AUTOSAR XML (schema 00049)
package /MICROSAR/Dcm_swc
  4 x mode declaration group, all with category=EXPLICIT_ORDER:
    DcmControlDtcSetting: initial-mode=ENABLEDTCSETTING, on-transition-value=2
      mode ENABLEDTCSETTING: value=0
      mode DISABLEDTCSETTING: value=1
    DcmEcuReset: initial-mode=NONE, on-transition-value=7
      7 x mode:
        NONE: value=0
        HARD: value=1
        KEYONOFF: value=2
        SOFT: value=3
        JUMPTOBOOTLOADER: value=4
        JUMPTOSYSSUPPLIERBOOTLOADER: value=5
        EXECUTE: value=6
    DcmDiagnosticSessionControl: initial-mode=DEFAULT_SESSION, on-transition-value=255
      mode DEFAULT_SESSION: value=1
      mode PROGRAMMING_SESSION: value=2
      mode EXTENDED_SESSION: value=3
    DcmCommunicationControl: initial-mode=DCM_ENABLE_RX_TX_NORM, on-transition-value=12
      12 x mode:
        DCM_ENABLE_RX_TX_NORM: value=0
        DCM_ENABLE_RX_DISABLE_TX_NORM: value=1
        DCM_DISABLE_RX_ENABLE_TX_NORM: value=2
        DCM_DISABLE_RX_TX_NORMAL: value=3
        DCM_ENABLE_RX_TX_NM: value=4
        DCM_ENABLE_RX_DISABLE_TX_NM: value=5
        DCM_DISABLE_RX_ENABLE_TX_NM: value=6
        DCM_DISABLE_RX_TX_NM: value=7
        DCM_ENABLE_RX_TX_NORM_NM: value=8
        DCM_ENABLE_RX_DISABLE_TX_NORM_NM: value=9
        DCM_DISABLE_RX_ENABLE_TX_NORM_NM: value=10
        DCM_DISABLE_RX_TX_NORM_NM: value=11
  data type mapping set DcmMappingSet  # Contains mapping for ModeDeclarationGroups which are provided by Dcm.
    mode-request-type-maps:
      implementation-data-type=Dcm_ControlDtcSettingType, mode-group=DcmControlDtcSetting
      implementation-data-type=Dcm_EcuResetType, mode-group=DcmEcuReset
      implementation-data-type=Dcm_DiagnosticSessionControlType, mode-group=DcmDiagnosticSessionControl
      implementation-data-type=Dcm_CommunicationModeType, mode-group=DcmCommunicationControl
package /MICROSAR/Dcm_swc/DataTypes
  70 x impl type:
    Dcm_ConfirmationStatusType: compu {0=DCM_RES_POS_OK, 1=DCM_RES_POS_NOT_OK, 2=DCM_RES_NEG_OK, 3=DCM_RES_NEG_NOT_OK}, range raw 0..3, implementation-data-type=uint8
    Dcm_OpStatusType: compu {0=DCM_INITIAL, 1=DCM_PENDING, 2=DCM_CANCEL, 3=DCM_FORCE_RCRRP_OK, 64=DCM_FORCE_RCRRP_NOT_OK}, range raw 0..64, implementation-data-type=uint8
    Dcm_NegativeResponseCodeType:
      compu {0=DCM_E_POSITIVERESPONSE, 16=DCM_E_GENERALREJECT, 17=DCM_E_SERVICENOTSUPPORTED, 18=DCM_E_SUBFUNCTIONNOTSUPPORTED, 19=DCM_E_INCORRECTMESSAGELENGTHORINVALIDFORMAT, 20=DCM_E_RESPONSETOOLONG, 33=DCM_E_BUSYREPEATREQUEST, 34=DCM_E_CONDITIONSNOTCORRECT, 36=DCM_E_REQUESTSEQUENCEERROR, 37=DCM_E_NORESPONSEFROMSUBNETCOMPONENT, 38=DCM_E_FAILUREPREVENTSEXECUTIONOFREQUESTEDACTION, 49=DCM_E_REQUESTOUTOFRANGE, 51=DCM_E_SECURITYACCESSDENIED, 52=DCM_E_AUTHENTICATIONREQUIRED, 53=DCM_E_INVALIDKEY, 54=DCM_E_EXCEEDNUMBEROFATTEMPTS, 55=DCM_E_REQUIREDTIMEDELAYNOTEXPIRED, 80=DCM_E_CVF_INVALIDTIMEPERIOD, 81=DCM_E_CVF_INVALIDSIGNATURE, 82=DCM_E_CVF_INVALIDCHAINOFTRUST, 83=DCM_E_CVF_INVALIDTYPE, 84=DCM_E_CVF_INVALIDFORMAT, 85=DCM_E_CVF_INVALIDCONTENT, 86=DCM_E_CVF_INVALIDSCOPE, 87=DCM_E_CVF_INVALIDCERTIFICATEREVOKED, 88=DCM_E_OWNERSHIPVERIFICATIONFAILED, 89=DCM_E_CHALLENGECALCULATIONFAILED, 112=DCM_E_UPLOADDOWNLOADNOTACCEPTED, 113=DCM_E_TRANSFERDATASUSPENDED, 114=DCM_E_GENERALPROGRAMMINGFAILURE, 115=DCM_E_WRONGBLOCKSEQUENCECOUNTER, 120=DCM_E_REQUESTCORRECTLYRECEIVEDRESPONSEPENDING, 126=DCM_E_SUBFUNCTIONNOTSUPPORTEDINACTIVESESSION, 127=DCM_E_SERVICENOTSUPPORTEDINACTIVESESSION, 129=DCM_E_RPMTOOHIGH, 130=DCM_E_RPMTOOLOW, 131=DCM_E_ENGINEISRUNNING, 132=DCM_E_ENGINEISNOTRUNNING, 133=DCM_E_ENGINERUNTIMETOOLOW, 134=DCM_E_TEMPERATURETOOHIGH, 135=DCM_E_TEMPERATURETOOLOW, 136=DCM_E_VEHICLESPEEDTOOHIGH, 137=DCM_E_VEHICLESPEEDTOOLOW, 138=DCM_E_THROTTLE_PEDALTOOHIGH, 139=DCM_E_THROTTLE_PEDALTOOLOW, 140=DCM_E_TRANSMISSIONRANGENOTINNEUTRAL, 141=DCM_E_TRANSMISSIONRANGENOTINGEAR, 143=DCM_E_BRAKESWITCH_NOTCLOSED, 144=DCM_E_SHIFTERLEVERNOTINPARK, 145=DCM_E_TORQUECONVERTERCLUTCHLOCKED, 146=DCM_E_VOLTAGETOOHIGH, 147=DCM_E_VOLTAGETOOLOW, 240..249=DCM_E_VMSCNC_0..DCM_E_VMSCNC_9, 250=DCM_E_VMSCNC_A, 251=DCM_E_VMSCNC_B, 252=DCM_E_VMSCNC_C, 253=DCM_E_VMSCNC_D, 254=DCM_E_VMSCNC_E}
      range raw 0..255
      implementation-data-type=uint8
    Dcm_ProtocolType: compu {0=DCM_OBD_ON_CAN, 1=DCM_OBD_ON_FLEXRAY, 2=DCM_OBD_ON_IP, 3=DCM_UDS_ON_CAN, 4=DCM_UDS_ON_FLEXRAY, 5=DCM_UDS_ON_IP, 12=DCM_NO_ACTIVE_PROTOCOL, 240..254=DCM_SUPPLIER_1..DCM_SUPPLIER_15}, range raw 0..254, implementation-data-type=uint8
    Dcm_RequestKindType: compu {0=DCM_REQ_KIND_NONE, 1=DCM_REQ_KIND_EXTERNAL, 2=DCM_REQ_KIND_ROE}, range raw 0..2, implementation-data-type=uint8
    Dcm_SecLevelType: compu {0=DCM_SEC_LEV_LOCKED, 1=DCM_SEC_LEV_L1, 2=DCM_SEC_LEV_L2}, range raw 0..2, implementation-data-type=uint8
    Dcm_SesCtrlType: compu {1=DCM_DEFAULT_SESSION, 2=DCM_PROGRAMMING_SESSION, 3=DCM_EXTENDED_DIAGNOSTIC_SESSION}, range raw 0..3, implementation-data-type=uint8
    Dcm_RequestDataArrayType: category=ARRAY, sw-calibration-access=READ-ONLY
      element Dcm_RequestDataArrayTypeElement: array-size=48, array-size-semantics=FIXED-SIZE, implementation-data-type=uint8
    Dcm_ControlDtcSettingType: compu {0=DCM_ENUM_ENABLEDTCSETTING, 1=DCM_ENUM_DISABLEDTCSETTING}, range raw 0..255, implementation-data-type=uint8
    Dcm_EcuResetType: compu {0=DCM_ENUM_NONE, 1=DCM_ENUM_HARD, 2=DCM_ENUM_KEYONOFF, 3=DCM_ENUM_SOFT, 4=DCM_ENUM_JUMPTOBOOTLOADER, 5=DCM_ENUM_JUMPTOSYSSUPPLIERBOOTLOADER, 6=DCM_ENUM_EXECUTE}, range raw 0..255, implementation-data-type=uint8
    Dcm_DiagnosticSessionControlType: compu {1=DCM_ENUM_DEFAULT_SESSION, 2=DCM_ENUM_PROGRAMMING_SESSION, 3=DCM_ENUM_EXTENDED_SESSION}, range raw 0..255, implementation-data-type=uint8
    Dcm_CommunicationModeType:
      compu {0=DCM_ENABLE_RX_TX_NORM, 1=DCM_ENABLE_RX_DISABLE_TX_NORM, 2=DCM_DISABLE_RX_ENABLE_TX_NORM, 3=DCM_DISABLE_RX_TX_NORMAL, 4=DCM_ENABLE_RX_TX_NM, 5=DCM_ENABLE_RX_DISABLE_TX_NM, 6=DCM_DISABLE_RX_ENABLE_TX_NM, 7=DCM_DISABLE_RX_TX_NM, 8=DCM_ENABLE_RX_TX_NORM_NM, 9=DCM_ENABLE_RX_DISABLE_TX_NORM_NM, 10=DCM_DISABLE_RX_ENABLE_TX_NORM_NM, 11=DCM_DISABLE_RX_TX_NORM_NM}
      range raw 0..255
      implementation-data-type=uint8
    Dcm_Data4ByteType: category=ARRAY, sw-calibration-access=READ-ONLY
      element Dcm_Data4ByteTypeElement: array-size=4, array-size-semantics=FIXED-SIZE, implementation-data-type=uint8
    Dcm_Data2ByteType: category=ARRAY, sw-calibration-access=READ-ONLY
      element Dcm_Data2ByteTypeElement: array-size=2, array-size-semantics=FIXED-SIZE, implementation-data-type=uint8
    Dcm_StartDataIn_SampleRoutineControl_In_Option0PrimitiveType: implementation-data-type=uint8
    Dcm_StartDataIn_SampleRoutineControl_In_Option0Type: implementation-data-type=Dcm_StartDataIn_SampleRoutineControl_In_Option0PrimitiveType
    Dcm_StartDataOut_SampleRoutineControl_Out_InitStatePrimitiveType: implementation-data-type=uint32
    Dcm_StartDataOut_SampleRoutineControl_Out_InitStateType: implementation-data-type=Dcm_StartDataOut_SampleRoutineControl_Out_InitStatePrimitiveType
    Dcm_StopDataOut_SampleRoutineControl_Out_StopStatePrimitiveType: implementation-data-type=uint32
    Dcm_StopDataOut_SampleRoutineControl_Out_StopStateType: implementation-data-type=Dcm_StopDataOut_SampleRoutineControl_Out_StopStatePrimitiveType
    Dcm_RequestDataOut_SampleRoutineControl_Out_ResultPrimitiveType: implementation-data-type=uint16
    Dcm_RequestDataOut_SampleRoutineControl_Out_ResultType: implementation-data-type=Dcm_RequestDataOut_SampleRoutineControl_Out_ResultPrimitiveType
    Dcm_StartDataIn_SampleRoutineControl_StartOnly_In_Option1ArrayType: implementation-data-type=uint8
    Dcm_StartDataIn_SampleRoutineControl_StartOnly_In_Option1Type: category=ARRAY, sw-calibration-access=READ-ONLY
      element Dcm_StartDataIn_SampleRoutineControl_StartOnly_In_Option1TypeElement: array-size=3, array-size-semantics=FIXED-SIZE, implementation-data-type=Dcm_StartDataIn_SampleRoutineControl_StartOnly_In_Option1ArrayType
    Dcm_RequestDataOut_SampleRoutineControl_StartOnly_Out_ResultPrimitiveType: implementation-data-type=uint32
    Dcm_RequestDataOut_SampleRoutineControl_StartOnly_Out_ResultType: implementation-data-type=Dcm_RequestDataOut_SampleRoutineControl_StartOnly_Out_ResultPrimitiveType
    Dcm_DataElement_DID_0xF413_DID_Data_PrimitiveType: implementation-data-type=uint16
    Dcm_DataElement_DID_0xF413_DID_DataType: implementation-data-type=Dcm_DataElement_DID_0xF413_DID_Data_PrimitiveType
    Dcm_DataElement_DID_0xF412_DID_Data_PrimitiveType: implementation-data-type=uint16
    Dcm_DataElement_DID_0xF412_DID_DataType: implementation-data-type=Dcm_DataElement_DID_0xF412_DID_Data_PrimitiveType
    Dcm_DataElement_DID_0xF410_DID_Data_PrimitiveType: implementation-data-type=uint16
    Dcm_DataElement_DID_0xF410_DID_DataType: implementation-data-type=Dcm_DataElement_DID_0xF410_DID_Data_PrimitiveType
    Dcm_Data15ByteType: category=ARRAY, sw-calibration-access=READ-ONLY
      element Dcm_Data15ByteTypeElement: array-size=15, array-size-semantics=FIXED-SIZE, implementation-data-type=uint8
    Dcm_Data17ByteType: category=ARRAY, sw-calibration-access=READ-ONLY
      element Dcm_Data17ByteTypeElement: array-size=17, array-size-semantics=FIXED-SIZE, implementation-data-type=uint8
    Dcm_DataElement_SerialNumber_SerialNumber_PrimitiveType: implementation-data-type=uint32
    Dcm_DataElement_SerialNumber_SerialNumberType: implementation-data-type=Dcm_DataElement_SerialNumber_SerialNumber_PrimitiveType
    Dcm_Data13ByteType: category=ARRAY, sw-calibration-access=READ-ONLY
      element Dcm_Data13ByteTypeElement: array-size=13, array-size-semantics=FIXED-SIZE, implementation-data-type=uint8
    Dcm_DataElement_Boot_Software_Boot_Software_Identification_PrimitiveType: implementation-data-type=uint32
    Dcm_DataElement_Boot_Software_Boot_Software_IdentificationType: implementation-data-type=Dcm_DataElement_Boot_Software_Boot_Software_Identification_PrimitiveType
    Dcm_DataElement_Boot_Software_NumberOfModules_PrimitiveType: implementation-data-type=uint8
    Dcm_DataElement_Boot_Software_NumberOfModulesType: implementation-data-type=Dcm_DataElement_Boot_Software_NumberOfModules_PrimitiveType
    Dcm_DataElement_DataDiagnosticIdentifier_DID_DataDiagnosticIdentifier_PrimitiveType: implementation-data-type=uint16
    Dcm_DataElement_DataDiagnosticIdentifier_DID_DataDiagnosticIdentifierType: implementation-data-type=Dcm_DataElement_DataDiagnosticIdentifier_DID_DataDiagnosticIdentifier_PrimitiveType
    Dcm_DataElement_DevelopmentData_TransportLayerVersion_PrimitiveType: implementation-data-type=uint16
    Dcm_DataElement_DevelopmentData_TransportLayerVersionType: implementation-data-type=Dcm_DataElement_DevelopmentData_TransportLayerVersion_PrimitiveType
    Dcm_DataElement_DevelopmentData_DiagnosticModuleVersion_PrimitiveType: implementation-data-type=uint16
    Dcm_DataElement_DevelopmentData_DiagnosticModuleVersionType: implementation-data-type=Dcm_DataElement_DevelopmentData_DiagnosticModuleVersion_PrimitiveType
    Dcm_DataElement_DevelopmentData_NmVersion_PrimitiveType: implementation-data-type=uint16
    Dcm_DataElement_DevelopmentData_NmVersionType: implementation-data-type=Dcm_DataElement_DevelopmentData_NmVersion_PrimitiveType
    Dcm_DataElement_DevelopmentData_CanDriverVersion_PrimitiveType: implementation-data-type=uint16
    Dcm_DataElement_DevelopmentData_CanDriverVersionType: implementation-data-type=Dcm_DataElement_DevelopmentData_CanDriverVersion_PrimitiveType
    Dcm_DataElement_DevelopmentData_OperatingSystemVersion_PrimitiveType: implementation-data-type=uint16
    Dcm_DataElement_DevelopmentData_OperatingSystemVersionType: implementation-data-type=Dcm_DataElement_DevelopmentData_OperatingSystemVersion_PrimitiveType
    Dcm_DataElement_DID_0x001B_DID_Sint8_Array_ArrayType: implementation-data-type=sint8
    Dcm_DataElement_DID_0x001B_DID_Sint8_ArrayType: category=ARRAY, sw-calibration-access=READ-ONLY
      element Dcm_DataElement_DID_0x001B_DID_Sint8_ArrayTypeElement: array-size=28, array-size-semantics=FIXED-SIZE, implementation-data-type=Dcm_DataElement_DID_0x001B_DID_Sint8_Array_ArrayType
    Dcm_DataElement_DID_0x001A_DID_Uint16_Array_ArrayType: implementation-data-type=uint16
    Dcm_DataElement_DID_0x001A_DID_Uint16_ArrayType: category=ARRAY, sw-calibration-access=READ-ONLY
      element Dcm_DataElement_DID_0x001A_DID_Uint16_ArrayTypeElement: array-size=4, array-size-semantics=FIXED-SIZE, implementation-data-type=Dcm_DataElement_DID_0x001A_DID_Uint16_Array_ArrayType
    Dcm_DataElement_DID_0x0019_DID_Sint16_Array_ArrayType: implementation-data-type=sint16
    Dcm_DataElement_DID_0x0019_DID_Sint16_ArrayType: category=ARRAY, sw-calibration-access=READ-ONLY
      element Dcm_DataElement_DID_0x0019_DID_Sint16_ArrayTypeElement: array-size=11, array-size-semantics=FIXED-SIZE, implementation-data-type=Dcm_DataElement_DID_0x0019_DID_Sint16_Array_ArrayType
    Dcm_DataElement_DID_0x0018_DID_Uint32_Array_ArrayType: implementation-data-type=uint32
    Dcm_DataElement_DID_0x0018_DID_Uint32_ArrayType: category=ARRAY, sw-calibration-access=READ-ONLY
      element Dcm_DataElement_DID_0x0018_DID_Uint32_ArrayTypeElement: array-size=6, array-size-semantics=FIXED-SIZE, implementation-data-type=Dcm_DataElement_DID_0x0018_DID_Uint32_Array_ArrayType
    Dcm_DataElement_DID_0x0017_DID_Sint32_Array_ArrayType: implementation-data-type=sint32
    Dcm_DataElement_DID_0x0017_DID_Sint32_ArrayType: category=ARRAY, sw-calibration-access=READ-ONLY
      element Dcm_DataElement_DID_0x0017_DID_Sint32_ArrayTypeElement: array-size=5, array-size-semantics=FIXED-SIZE, implementation-data-type=Dcm_DataElement_DID_0x0017_DID_Sint32_Array_ArrayType
    Dcm_DataElement_Example_WriteOnlyDID_DID_DataObject_PrimitiveType: implementation-data-type=uint8
    Dcm_DataElement_Example_WriteOnlyDID_DID_DataObjectType: implementation-data-type=Dcm_DataElement_Example_WriteOnlyDID_DID_DataObject_PrimitiveType
    Dcm_DataElement_SampleIoControl_DID_Data_PrimitiveType: implementation-data-type=uint32
    Dcm_DataElement_SampleIoControl_DID_DataType: implementation-data-type=Dcm_DataElement_SampleIoControl_DID_Data_PrimitiveType
    Dcm_DataElement_Example_ReadWriteData_GlobalTime_PrimitiveType: implementation-data-type=uint32
    Dcm_DataElement_Example_ReadWriteData_GlobalTimeType: implementation-data-type=Dcm_DataElement_Example_ReadWriteData_GlobalTime_PrimitiveType
    Dcm_Data6ByteType: category=ARRAY, sw-calibration-access=READ-ONLY
      element Dcm_Data6ByteTypeElement: array-size=6, array-size-semantics=FIXED-SIZE, implementation-data-type=uint8
package /MICROSAR/Dcm_swc/Interfaces
  4 x mode switch interface, all with is-service=true, service-kind=DIAGNOSTIC-COMMUNICATION-MANAGER:
    DcmControlDtcSetting
      mode group DcmControlDtcSetting: type=DcmControlDtcSetting
    DcmEcuReset
      mode group DcmEcuReset: type=DcmEcuReset
    DcmDiagnosticSessionControl
      mode group DcmDiagnosticSessionControl: type=DcmDiagnosticSessionControl
    DcmCommunicationControl_ComMConf_ComMChannel_CN_CAN00_a2373004
      mode group DcmCommunicationControl_ComMConf_ComMChannel_CN_CAN00_a2373004: type=DcmCommunicationControl
  30 x client server interface, all with is-service=true, service-kind=DIAGNOSTIC-COMMUNICATION-MANAGER:
    DCMServices
      6 x operation:
        GetActiveProtocol: possible-error=E_OK
          arg ActiveProtocol: type=Dcm_ProtocolType, direction=OUT
        GetSesCtrlType: possible-error=E_OK
          arg SesCtrlType: type=Dcm_SesCtrlType, direction=OUT
        ResetToDefaultSession: possible-error=E_OK
        GetSecurityLevel: possible-error=E_OK
          arg SecLevel: type=Dcm_SecLevelType, direction=OUT
        SetActiveDiagnostic: possible-error=E_OK
          arg active: type=boolean, direction=IN
        GetRequestKind: possible-error=DCMServices/E_NOT_OK
          arg TesterSourceAddress: type=uint16, direction=IN
          arg RequestKind: type=Dcm_RequestKindType, direction=OUT
      error E_OK: error-code=0
      error E_NOT_OK: error-code=1
    SecurityAccess_UnlockedL1
      operation GetSeed: possible-error=[SecurityAccess_UnlockedL1/E_NOT_OK, SecurityAccess_UnlockedL1/DCM_E_PENDING]
        arg OpStatus: type=Dcm_OpStatusType, direction=IN
        arg Seed: type=Dcm_Data4ByteType, direction=OUT
        arg ErrorCode: type=Dcm_NegativeResponseCodeType, direction=OUT
      operation CompareKey: possible-error=[SecurityAccess_UnlockedL1/E_NOT_OK, SecurityAccess_UnlockedL1/DCM_E_PENDING, SecurityAccess_UnlockedL1/DCM_E_COMPARE_KEY_FAILED]
        arg Key: type=Dcm_Data4ByteType, direction=IN
        arg OpStatus: type=Dcm_OpStatusType, direction=IN
        arg ErrorCode: type=Dcm_NegativeResponseCodeType, direction=OUT
      error E_NOT_OK: error-code=1
      error DCM_E_PENDING: error-code=10
      error DCM_E_COMPARE_KEY_FAILED: error-code=11
    SecurityAccess_Level_3
      operation GetSeed: possible-error=[SecurityAccess_Level_3/E_NOT_OK, SecurityAccess_Level_3/DCM_E_PENDING]
        arg OpStatus: type=Dcm_OpStatusType, direction=IN
        arg Seed: type=Dcm_Data2ByteType, direction=OUT
        arg ErrorCode: type=Dcm_NegativeResponseCodeType, direction=OUT
      operation CompareKey: possible-error=[SecurityAccess_Level_3/E_NOT_OK, SecurityAccess_Level_3/DCM_E_PENDING, SecurityAccess_Level_3/DCM_E_COMPARE_KEY_FAILED]
        arg Key: type=Dcm_Data2ByteType, direction=IN
        arg OpStatus: type=Dcm_OpStatusType, direction=IN
        arg ErrorCode: type=Dcm_NegativeResponseCodeType, direction=OUT
      error E_NOT_OK: error-code=1
      error DCM_E_PENDING: error-code=10
      error DCM_E_COMPARE_KEY_FAILED: error-code=11
    RoutineServices_SampleRoutineControl
      operation Start: possible-error=[RoutineServices_SampleRoutineControl/E_NOT_OK, RoutineServices_SampleRoutineControl/DCM_E_PENDING, RoutineServices_SampleRoutineControl/DCM_E_FORCE_RCRRP]
        4 x arg:
          In_Option0: type=Dcm_StartDataIn_SampleRoutineControl_In_Option0Type, direction=IN
          OpStatus: type=Dcm_OpStatusType, direction=IN
          Out_InitState: type=Dcm_StartDataOut_SampleRoutineControl_Out_InitStateType, direction=OUT
          ErrorCode: type=Dcm_NegativeResponseCodeType, direction=OUT
      operation Stop: possible-error=[RoutineServices_SampleRoutineControl/E_NOT_OK, RoutineServices_SampleRoutineControl/DCM_E_PENDING, RoutineServices_SampleRoutineControl/DCM_E_FORCE_RCRRP]
        arg OpStatus: type=Dcm_OpStatusType, direction=IN
        arg Out_StopState: type=Dcm_StopDataOut_SampleRoutineControl_Out_StopStateType, direction=OUT
        arg ErrorCode: type=Dcm_NegativeResponseCodeType, direction=OUT
      operation RequestResults: possible-error=[RoutineServices_SampleRoutineControl/E_NOT_OK, RoutineServices_SampleRoutineControl/DCM_E_PENDING, RoutineServices_SampleRoutineControl/DCM_E_FORCE_RCRRP]
        arg OpStatus: type=Dcm_OpStatusType, direction=IN
        arg Out_Result: type=Dcm_RequestDataOut_SampleRoutineControl_Out_ResultType, direction=OUT
        arg ErrorCode: type=Dcm_NegativeResponseCodeType, direction=OUT
      error E_NOT_OK: error-code=1
      error DCM_E_PENDING: error-code=10
      error DCM_E_FORCE_RCRRP: error-code=12
    RoutineServices_SampleRoutineControl_StartOnly
      operation Start: possible-error=[RoutineServices_SampleRoutineControl_StartOnly/E_NOT_OK, RoutineServices_SampleRoutineControl_StartOnly/DCM_E_PENDING, RoutineServices_SampleRoutineControl_StartOnly/DCM_E_FORCE_RCRRP]
        arg In_Option1: type=Dcm_StartDataIn_SampleRoutineControl_StartOnly_In_Option1Type, direction=IN
        arg OpStatus: type=Dcm_OpStatusType, direction=IN
        arg ErrorCode: type=Dcm_NegativeResponseCodeType, direction=OUT
      operation RequestResults: possible-error=[RoutineServices_SampleRoutineControl_StartOnly/E_NOT_OK, RoutineServices_SampleRoutineControl_StartOnly/DCM_E_PENDING, RoutineServices_SampleRoutineControl_StartOnly/DCM_E_FORCE_RCRRP]
        arg OpStatus: type=Dcm_OpStatusType, direction=IN
        arg Out_Result: type=Dcm_RequestDataOut_SampleRoutineControl_StartOnly_Out_ResultType, direction=OUT
        arg ErrorCode: type=Dcm_NegativeResponseCodeType, direction=OUT
      error E_NOT_OK: error-code=1
      error DCM_E_PENDING: error-code=10
      error DCM_E_FORCE_RCRRP: error-code=12
    DataServices_DID_0xF413_DID_Data
      operation ReadData: possible-error=[DataServices_DID_0xF413_DID_Data/E_NOT_OK, DataServices_DID_0xF413_DID_Data/DCM_E_PENDING]
        arg OpStatus: type=Dcm_OpStatusType, direction=IN
        arg Data: type=Dcm_DataElement_DID_0xF413_DID_DataType, direction=OUT
      operation ConditionCheckRead: possible-error=[DataServices_DID_0xF413_DID_Data/E_NOT_OK, DataServices_DID_0xF413_DID_Data/DCM_E_PENDING]
        arg OpStatus: type=Dcm_OpStatusType, direction=IN
        arg ErrorCode: type=Dcm_NegativeResponseCodeType, direction=OUT
      error E_NOT_OK: error-code=1
      error DCM_E_PENDING: error-code=10
    DataServices_DID_0xF412_DID_Data
      operation ReadData: possible-error=[DataServices_DID_0xF412_DID_Data/E_NOT_OK, DataServices_DID_0xF412_DID_Data/DCM_E_PENDING]
        arg OpStatus: type=Dcm_OpStatusType, direction=IN
        arg Data: type=Dcm_DataElement_DID_0xF412_DID_DataType, direction=OUT
      operation ConditionCheckRead: possible-error=[DataServices_DID_0xF412_DID_Data/E_NOT_OK, DataServices_DID_0xF412_DID_Data/DCM_E_PENDING]
        arg OpStatus: type=Dcm_OpStatusType, direction=IN
        arg ErrorCode: type=Dcm_NegativeResponseCodeType, direction=OUT
      error E_NOT_OK: error-code=1
      error DCM_E_PENDING: error-code=10
    DataServices_DID_0xF410_DID_Data
      operation ReadData: possible-error=[DataServices_DID_0xF410_DID_Data/E_NOT_OK, DataServices_DID_0xF410_DID_Data/DCM_E_PENDING]
        arg OpStatus: type=Dcm_OpStatusType, direction=IN
        arg Data: type=Dcm_DataElement_DID_0xF410_DID_DataType, direction=OUT
      operation ConditionCheckRead: possible-error=[DataServices_DID_0xF410_DID_Data/E_NOT_OK, DataServices_DID_0xF410_DID_Data/DCM_E_PENDING]
        arg OpStatus: type=Dcm_OpStatusType, direction=IN
        arg ErrorCode: type=Dcm_NegativeResponseCodeType, direction=OUT
      error E_NOT_OK: error-code=1
      error DCM_E_PENDING: error-code=10
    DataServices_Hardware_Version_Hardware_Version_Number
      operation ReadData: possible-error=[DataServices_Hardware_Version_Hardware_Version_Number/E_NOT_OK, DataServices_Hardware_Version_Hardware_Version_Number/DCM_E_PENDING]
        arg OpStatus: type=Dcm_OpStatusType, direction=IN
        arg Data: type=Dcm_Data15ByteType, direction=OUT
      operation ConditionCheckRead: possible-error=[DataServices_Hardware_Version_Hardware_Version_Number/E_NOT_OK, DataServices_Hardware_Version_Hardware_Version_Number/DCM_E_PENDING]
        arg OpStatus: type=Dcm_OpStatusType, direction=IN
        arg ErrorCode: type=Dcm_NegativeResponseCodeType, direction=OUT
      operation WriteData: possible-error=[DataServices_Hardware_Version_Hardware_Version_Number/E_NOT_OK, DataServices_Hardware_Version_Hardware_Version_Number/DCM_E_PENDING]
        arg Data: type=Dcm_Data15ByteType, direction=IN
        arg OpStatus: type=Dcm_OpStatusType, direction=IN
        arg ErrorCode: type=Dcm_NegativeResponseCodeType, direction=OUT
      error E_NOT_OK: error-code=1
      error DCM_E_PENDING: error-code=10
    DataServices_Vehicle_Identification_VIN
      operation ReadData: possible-error=[DataServices_Vehicle_Identification_VIN/E_NOT_OK, DataServices_Vehicle_Identification_VIN/DCM_E_PENDING]
        arg OpStatus: type=Dcm_OpStatusType, direction=IN
        arg Data: type=Dcm_Data17ByteType, direction=OUT
      operation ConditionCheckRead: possible-error=[DataServices_Vehicle_Identification_VIN/E_NOT_OK, DataServices_Vehicle_Identification_VIN/DCM_E_PENDING]
        arg OpStatus: type=Dcm_OpStatusType, direction=IN
        arg ErrorCode: type=Dcm_NegativeResponseCodeType, direction=OUT
      operation WriteData: possible-error=[DataServices_Vehicle_Identification_VIN/E_NOT_OK, DataServices_Vehicle_Identification_VIN/DCM_E_PENDING]
        arg Data: type=Dcm_Data17ByteType, direction=IN
        arg OpStatus: type=Dcm_OpStatusType, direction=IN
        arg ErrorCode: type=Dcm_NegativeResponseCodeType, direction=OUT
      error E_NOT_OK: error-code=1
      error DCM_E_PENDING: error-code=10
    DataServices_SerialNumber_SerialNumber
      operation ReadData: possible-error=[DataServices_SerialNumber_SerialNumber/E_NOT_OK, DataServices_SerialNumber_SerialNumber/DCM_E_PENDING]
        arg OpStatus: type=Dcm_OpStatusType, direction=IN
        arg Data: type=Dcm_DataElement_SerialNumber_SerialNumberType, direction=OUT
      operation ConditionCheckRead: possible-error=[DataServices_SerialNumber_SerialNumber/E_NOT_OK, DataServices_SerialNumber_SerialNumber/DCM_E_PENDING]
        arg OpStatus: type=Dcm_OpStatusType, direction=IN
        arg ErrorCode: type=Dcm_NegativeResponseCodeType, direction=OUT
      operation WriteData: possible-error=[DataServices_SerialNumber_SerialNumber/E_NOT_OK, DataServices_SerialNumber_SerialNumber/DCM_E_PENDING]
        arg Data: type=Dcm_DataElement_SerialNumber_SerialNumberType, direction=IN
        arg OpStatus: type=Dcm_OpStatusType, direction=IN
        arg ErrorCode: type=Dcm_NegativeResponseCodeType, direction=OUT
      error E_NOT_OK: error-code=1
      error DCM_E_PENDING: error-code=10
    DataServices_EcuIdentification_Part_Number
      operation ReadData: possible-error=[DataServices_EcuIdentification_Part_Number/E_NOT_OK, DataServices_EcuIdentification_Part_Number/DCM_E_PENDING]
        arg OpStatus: type=Dcm_OpStatusType, direction=IN
        arg Data: type=Dcm_Data13ByteType, direction=OUT
      operation ConditionCheckRead: possible-error=[DataServices_EcuIdentification_Part_Number/E_NOT_OK, DataServices_EcuIdentification_Part_Number/DCM_E_PENDING]
        arg OpStatus: type=Dcm_OpStatusType, direction=IN
        arg ErrorCode: type=Dcm_NegativeResponseCodeType, direction=OUT
      operation WriteData: possible-error=[DataServices_EcuIdentification_Part_Number/E_NOT_OK, DataServices_EcuIdentification_Part_Number/DCM_E_PENDING]
        arg Data: type=Dcm_Data13ByteType, direction=IN
        arg OpStatus: type=Dcm_OpStatusType, direction=IN
        arg ErrorCode: type=Dcm_NegativeResponseCodeType, direction=OUT
      error E_NOT_OK: error-code=1
      error DCM_E_PENDING: error-code=10
    DataServices_Spare_Part_Number_Spare_Part_Number
      operation ReadData: possible-error=[DataServices_Spare_Part_Number_Spare_Part_Number/E_NOT_OK, DataServices_Spare_Part_Number_Spare_Part_Number/DCM_E_PENDING]
        arg OpStatus: type=Dcm_OpStatusType, direction=IN
        arg Data: type=Dcm_Data13ByteType, direction=OUT
      operation ConditionCheckRead: possible-error=[DataServices_Spare_Part_Number_Spare_Part_Number/E_NOT_OK, DataServices_Spare_Part_Number_Spare_Part_Number/DCM_E_PENDING]
        arg OpStatus: type=Dcm_OpStatusType, direction=IN
        arg ErrorCode: type=Dcm_NegativeResponseCodeType, direction=OUT
      operation WriteData: possible-error=[DataServices_Spare_Part_Number_Spare_Part_Number/E_NOT_OK, DataServices_Spare_Part_Number_Spare_Part_Number/DCM_E_PENDING]
        arg Data: type=Dcm_Data13ByteType, direction=IN
        arg OpStatus: type=Dcm_OpStatusType, direction=IN
        arg ErrorCode: type=Dcm_NegativeResponseCodeType, direction=OUT
      error E_NOT_OK: error-code=1
      error DCM_E_PENDING: error-code=10
    DataServices_Boot_Software_Boot_Software_Identification
      operation ReadData: possible-error=[DataServices_Boot_Software_Boot_Software_Identification/E_NOT_OK, DataServices_Boot_Software_Boot_Software_Identification/DCM_E_PENDING]
        arg OpStatus: type=Dcm_OpStatusType, direction=IN
        arg Data: type=Dcm_DataElement_Boot_Software_Boot_Software_IdentificationType, direction=OUT
      operation ConditionCheckRead: possible-error=[DataServices_Boot_Software_Boot_Software_Identification/E_NOT_OK, DataServices_Boot_Software_Boot_Software_Identification/DCM_E_PENDING]
        arg OpStatus: type=Dcm_OpStatusType, direction=IN
        arg ErrorCode: type=Dcm_NegativeResponseCodeType, direction=OUT
      operation WriteData: possible-error=[DataServices_Boot_Software_Boot_Software_Identification/E_NOT_OK, DataServices_Boot_Software_Boot_Software_Identification/DCM_E_PENDING]
        arg Data: type=Dcm_DataElement_Boot_Software_Boot_Software_IdentificationType, direction=IN
        arg OpStatus: type=Dcm_OpStatusType, direction=IN
        arg ErrorCode: type=Dcm_NegativeResponseCodeType, direction=OUT
      error E_NOT_OK: error-code=1
      error DCM_E_PENDING: error-code=10
    DataServices_Boot_Software_NumberOfModules
      operation ReadData: possible-error=[DataServices_Boot_Software_NumberOfModules/E_NOT_OK, DataServices_Boot_Software_NumberOfModules/DCM_E_PENDING]
        arg OpStatus: type=Dcm_OpStatusType, direction=IN
        arg Data: type=Dcm_DataElement_Boot_Software_NumberOfModulesType, direction=OUT
      operation ConditionCheckRead: possible-error=[DataServices_Boot_Software_NumberOfModules/E_NOT_OK, DataServices_Boot_Software_NumberOfModules/DCM_E_PENDING]
        arg OpStatus: type=Dcm_OpStatusType, direction=IN
        arg ErrorCode: type=Dcm_NegativeResponseCodeType, direction=OUT
      operation WriteData: possible-error=[DataServices_Boot_Software_NumberOfModules/E_NOT_OK, DataServices_Boot_Software_NumberOfModules/DCM_E_PENDING]
        arg Data: type=Dcm_DataElement_Boot_Software_NumberOfModulesType, direction=IN
        arg OpStatus: type=Dcm_OpStatusType, direction=IN
        arg ErrorCode: type=Dcm_NegativeResponseCodeType, direction=OUT
      error E_NOT_OK: error-code=1
      error DCM_E_PENDING: error-code=10
    DataServices_DataDiagnosticIdentifier_DID_DataDiagnosticIdentifier
      operation ReadData: possible-error=[DataServices_DataDiagnosticIdentifier_DID_DataDiagnosticIdentifier/E_NOT_OK, DataServices_DataDiagnosticIdentifier_DID_DataDiagnosticIdentifier/DCM_E_PENDING]
        arg OpStatus: type=Dcm_OpStatusType, direction=IN
        arg Data: type=Dcm_DataElement_DataDiagnosticIdentifier_DID_DataDiagnosticIdentifierType, direction=OUT
      operation ConditionCheckRead: possible-error=[DataServices_DataDiagnosticIdentifier_DID_DataDiagnosticIdentifier/E_NOT_OK, DataServices_DataDiagnosticIdentifier_DID_DataDiagnosticIdentifier/DCM_E_PENDING]
        arg OpStatus: type=Dcm_OpStatusType, direction=IN
        arg ErrorCode: type=Dcm_NegativeResponseCodeType, direction=OUT
      operation WriteData: possible-error=[DataServices_DataDiagnosticIdentifier_DID_DataDiagnosticIdentifier/E_NOT_OK, DataServices_DataDiagnosticIdentifier_DID_DataDiagnosticIdentifier/DCM_E_PENDING]
        arg Data: type=Dcm_DataElement_DataDiagnosticIdentifier_DID_DataDiagnosticIdentifierType, direction=IN
        arg OpStatus: type=Dcm_OpStatusType, direction=IN
        arg ErrorCode: type=Dcm_NegativeResponseCodeType, direction=OUT
      error E_NOT_OK: error-code=1
      error DCM_E_PENDING: error-code=10
    DataServices_DevelopmentData_TransportLayerVersion
      operation ReadData: possible-error=[DataServices_DevelopmentData_TransportLayerVersion/E_NOT_OK, DataServices_DevelopmentData_TransportLayerVersion/DCM_E_PENDING]
        arg OpStatus: type=Dcm_OpStatusType, direction=IN
        arg Data: type=Dcm_DataElement_DevelopmentData_TransportLayerVersionType, direction=OUT
      operation ConditionCheckRead: possible-error=[DataServices_DevelopmentData_TransportLayerVersion/E_NOT_OK, DataServices_DevelopmentData_TransportLayerVersion/DCM_E_PENDING]
        arg OpStatus: type=Dcm_OpStatusType, direction=IN
        arg ErrorCode: type=Dcm_NegativeResponseCodeType, direction=OUT
      operation WriteData: possible-error=[DataServices_DevelopmentData_TransportLayerVersion/E_NOT_OK, DataServices_DevelopmentData_TransportLayerVersion/DCM_E_PENDING]
        arg Data: type=Dcm_DataElement_DevelopmentData_TransportLayerVersionType, direction=IN
        arg OpStatus: type=Dcm_OpStatusType, direction=IN
        arg ErrorCode: type=Dcm_NegativeResponseCodeType, direction=OUT
      error E_NOT_OK: error-code=1
      error DCM_E_PENDING: error-code=10
    DataServices_DevelopmentData_DiagnosticModuleVersion
      operation ReadData: possible-error=[DataServices_DevelopmentData_DiagnosticModuleVersion/E_NOT_OK, DataServices_DevelopmentData_DiagnosticModuleVersion/DCM_E_PENDING]
        arg OpStatus: type=Dcm_OpStatusType, direction=IN
        arg Data: type=Dcm_DataElement_DevelopmentData_DiagnosticModuleVersionType, direction=OUT
      operation ConditionCheckRead: possible-error=[DataServices_DevelopmentData_DiagnosticModuleVersion/E_NOT_OK, DataServices_DevelopmentData_DiagnosticModuleVersion/DCM_E_PENDING]
        arg OpStatus: type=Dcm_OpStatusType, direction=IN
        arg ErrorCode: type=Dcm_NegativeResponseCodeType, direction=OUT
      operation WriteData: possible-error=[DataServices_DevelopmentData_DiagnosticModuleVersion/E_NOT_OK, DataServices_DevelopmentData_DiagnosticModuleVersion/DCM_E_PENDING]
        arg Data: type=Dcm_DataElement_DevelopmentData_DiagnosticModuleVersionType, direction=IN
        arg OpStatus: type=Dcm_OpStatusType, direction=IN
        arg ErrorCode: type=Dcm_NegativeResponseCodeType, direction=OUT
      error E_NOT_OK: error-code=1
      error DCM_E_PENDING: error-code=10
    DataServices_DevelopmentData_NmVersion
      operation ReadData: possible-error=[DataServices_DevelopmentData_NmVersion/E_NOT_OK, DataServices_DevelopmentData_NmVersion/DCM_E_PENDING]
        arg OpStatus: type=Dcm_OpStatusType, direction=IN
        arg Data: type=Dcm_DataElement_DevelopmentData_NmVersionType, direction=OUT
      operation ConditionCheckRead: possible-error=[DataServices_DevelopmentData_NmVersion/E_NOT_OK, DataServices_DevelopmentData_NmVersion/DCM_E_PENDING]
        arg OpStatus: type=Dcm_OpStatusType, direction=IN
        arg ErrorCode: type=Dcm_NegativeResponseCodeType, direction=OUT
      operation WriteData: possible-error=[DataServices_DevelopmentData_NmVersion/E_NOT_OK, DataServices_DevelopmentData_NmVersion/DCM_E_PENDING]
        arg Data: type=Dcm_DataElement_DevelopmentData_NmVersionType, direction=IN
        arg OpStatus: type=Dcm_OpStatusType, direction=IN
        arg ErrorCode: type=Dcm_NegativeResponseCodeType, direction=OUT
      error E_NOT_OK: error-code=1
      error DCM_E_PENDING: error-code=10
    DataServices_DevelopmentData_CanDriverVersion
      operation ReadData: possible-error=[DataServices_DevelopmentData_CanDriverVersion/E_NOT_OK, DataServices_DevelopmentData_CanDriverVersion/DCM_E_PENDING]
        arg OpStatus: type=Dcm_OpStatusType, direction=IN
        arg Data: type=Dcm_DataElement_DevelopmentData_CanDriverVersionType, direction=OUT
      operation ConditionCheckRead: possible-error=[DataServices_DevelopmentData_CanDriverVersion/E_NOT_OK, DataServices_DevelopmentData_CanDriverVersion/DCM_E_PENDING]
        arg OpStatus: type=Dcm_OpStatusType, direction=IN
        arg ErrorCode: type=Dcm_NegativeResponseCodeType, direction=OUT
      operation WriteData: possible-error=[DataServices_DevelopmentData_CanDriverVersion/E_NOT_OK, DataServices_DevelopmentData_CanDriverVersion/DCM_E_PENDING]
        arg Data: type=Dcm_DataElement_DevelopmentData_CanDriverVersionType, direction=IN
        arg OpStatus: type=Dcm_OpStatusType, direction=IN
        arg ErrorCode: type=Dcm_NegativeResponseCodeType, direction=OUT
      error E_NOT_OK: error-code=1
      error DCM_E_PENDING: error-code=10
    DataServices_DevelopmentData_OperatingSystemVersion
      operation ReadData: possible-error=[DataServices_DevelopmentData_OperatingSystemVersion/E_NOT_OK, DataServices_DevelopmentData_OperatingSystemVersion/DCM_E_PENDING]
        arg OpStatus: type=Dcm_OpStatusType, direction=IN
        arg Data: type=Dcm_DataElement_DevelopmentData_OperatingSystemVersionType, direction=OUT
      operation ConditionCheckRead: possible-error=[DataServices_DevelopmentData_OperatingSystemVersion/E_NOT_OK, DataServices_DevelopmentData_OperatingSystemVersion/DCM_E_PENDING]
        arg OpStatus: type=Dcm_OpStatusType, direction=IN
        arg ErrorCode: type=Dcm_NegativeResponseCodeType, direction=OUT
      operation WriteData: possible-error=[DataServices_DevelopmentData_OperatingSystemVersion/E_NOT_OK, DataServices_DevelopmentData_OperatingSystemVersion/DCM_E_PENDING]
        arg Data: type=Dcm_DataElement_DevelopmentData_OperatingSystemVersionType, direction=IN
        arg OpStatus: type=Dcm_OpStatusType, direction=IN
        arg ErrorCode: type=Dcm_NegativeResponseCodeType, direction=OUT
      error E_NOT_OK: error-code=1
      error DCM_E_PENDING: error-code=10
    DataServices_DID_0x001B_DID_Sint8_Array
      operation WriteData: possible-error=[DataServices_DID_0x001B_DID_Sint8_Array/E_NOT_OK, DataServices_DID_0x001B_DID_Sint8_Array/DCM_E_PENDING]
        arg Data: type=Dcm_DataElement_DID_0x001B_DID_Sint8_ArrayType, direction=IN
        arg OpStatus: type=Dcm_OpStatusType, direction=IN
        arg ErrorCode: type=Dcm_NegativeResponseCodeType, direction=OUT
      error E_NOT_OK: error-code=1
      error DCM_E_PENDING: error-code=10
    DataServices_DID_0x001A_DID_Uint16_Array
      operation ReadData: possible-error=[DataServices_DID_0x001A_DID_Uint16_Array/E_NOT_OK, DataServices_DID_0x001A_DID_Uint16_Array/DCM_E_PENDING]
        arg OpStatus: type=Dcm_OpStatusType, direction=IN
        arg Data: type=Dcm_DataElement_DID_0x001A_DID_Uint16_ArrayType, direction=OUT
      operation ConditionCheckRead: possible-error=[DataServices_DID_0x001A_DID_Uint16_Array/E_NOT_OK, DataServices_DID_0x001A_DID_Uint16_Array/DCM_E_PENDING]
        arg OpStatus: type=Dcm_OpStatusType, direction=IN
        arg ErrorCode: type=Dcm_NegativeResponseCodeType, direction=OUT
      operation WriteData: possible-error=[DataServices_DID_0x001A_DID_Uint16_Array/E_NOT_OK, DataServices_DID_0x001A_DID_Uint16_Array/DCM_E_PENDING]
        arg Data: type=Dcm_DataElement_DID_0x001A_DID_Uint16_ArrayType, direction=IN
        arg OpStatus: type=Dcm_OpStatusType, direction=IN
        arg ErrorCode: type=Dcm_NegativeResponseCodeType, direction=OUT
      error E_NOT_OK: error-code=1
      error DCM_E_PENDING: error-code=10
    DataServices_DID_0x0019_DID_Sint16_Array
      operation ReadData: possible-error=[DataServices_DID_0x0019_DID_Sint16_Array/E_NOT_OK, DataServices_DID_0x0019_DID_Sint16_Array/DCM_E_PENDING]
        arg OpStatus: type=Dcm_OpStatusType, direction=IN
        arg Data: type=Dcm_DataElement_DID_0x0019_DID_Sint16_ArrayType, direction=OUT
      operation ConditionCheckRead: possible-error=[DataServices_DID_0x0019_DID_Sint16_Array/E_NOT_OK, DataServices_DID_0x0019_DID_Sint16_Array/DCM_E_PENDING]
        arg OpStatus: type=Dcm_OpStatusType, direction=IN
        arg ErrorCode: type=Dcm_NegativeResponseCodeType, direction=OUT
      error E_NOT_OK: error-code=1
      error DCM_E_PENDING: error-code=10
    DataServices_DID_0x0018_DID_Uint32_Array
      operation ReadData: possible-error=[DataServices_DID_0x0018_DID_Uint32_Array/E_NOT_OK, DataServices_DID_0x0018_DID_Uint32_Array/DCM_E_PENDING]
        arg OpStatus: type=Dcm_OpStatusType, direction=IN
        arg Data: type=Dcm_DataElement_DID_0x0018_DID_Uint32_ArrayType, direction=OUT
      operation ConditionCheckRead: possible-error=[DataServices_DID_0x0018_DID_Uint32_Array/E_NOT_OK, DataServices_DID_0x0018_DID_Uint32_Array/DCM_E_PENDING]
        arg OpStatus: type=Dcm_OpStatusType, direction=IN
        arg ErrorCode: type=Dcm_NegativeResponseCodeType, direction=OUT
      operation WriteData: possible-error=[DataServices_DID_0x0018_DID_Uint32_Array/E_NOT_OK, DataServices_DID_0x0018_DID_Uint32_Array/DCM_E_PENDING]
        arg Data: type=Dcm_DataElement_DID_0x0018_DID_Uint32_ArrayType, direction=IN
        arg OpStatus: type=Dcm_OpStatusType, direction=IN
        arg ErrorCode: type=Dcm_NegativeResponseCodeType, direction=OUT
      error E_NOT_OK: error-code=1
      error DCM_E_PENDING: error-code=10
    DataServices_DID_0x0017_DID_Sint32_Array
      operation WriteData: possible-error=[DataServices_DID_0x0017_DID_Sint32_Array/E_NOT_OK, DataServices_DID_0x0017_DID_Sint32_Array/DCM_E_PENDING]
        arg Data: type=Dcm_DataElement_DID_0x0017_DID_Sint32_ArrayType, direction=IN
        arg OpStatus: type=Dcm_OpStatusType, direction=IN
        arg ErrorCode: type=Dcm_NegativeResponseCodeType, direction=OUT
      error E_NOT_OK: error-code=1
      error DCM_E_PENDING: error-code=10
    DataServices_Example_WriteOnlyDID_DID_DataObject
      operation WriteData: possible-error=[DataServices_Example_WriteOnlyDID_DID_DataObject/E_NOT_OK, DataServices_Example_WriteOnlyDID_DID_DataObject/DCM_E_PENDING]
        arg Data: type=Dcm_DataElement_Example_WriteOnlyDID_DID_DataObjectType, direction=IN
        arg OpStatus: type=Dcm_OpStatusType, direction=IN
        arg ErrorCode: type=Dcm_NegativeResponseCodeType, direction=OUT
      error E_NOT_OK: error-code=1
      error DCM_E_PENDING: error-code=10
    DataServices_SampleIoControl_DID_Data
      5 x operation, all with possible-error=[DataServices_SampleIoControl_DID_Data/E_NOT_OK, DataServices_SampleIoControl_DID_Data/DCM_E_PENDING]:
        ReadData
          arg OpStatus: type=Dcm_OpStatusType, direction=IN
          arg Data: type=Dcm_DataElement_SampleIoControl_DID_DataType, direction=OUT
        ReturnControlToECU
          arg OpStatus: type=Dcm_OpStatusType, direction=IN
          arg ErrorCode: type=Dcm_NegativeResponseCodeType, direction=OUT
        ResetToDefault
          arg OpStatus: type=Dcm_OpStatusType, direction=IN
          arg ErrorCode: type=Dcm_NegativeResponseCodeType, direction=OUT
        FreezeCurrentState
          arg OpStatus: type=Dcm_OpStatusType, direction=IN
          arg ErrorCode: type=Dcm_NegativeResponseCodeType, direction=OUT
        ShortTermAdjustment
          arg Data: type=Dcm_Data4ByteType, direction=IN
          arg OpStatus: type=Dcm_OpStatusType, direction=IN
          arg ErrorCode: type=Dcm_NegativeResponseCodeType, direction=OUT
      error E_NOT_OK: error-code=1
      error DCM_E_PENDING: error-code=10
    DataServices_Example_ReadWriteData_GlobalTime
      operation ReadData: possible-error=[DataServices_Example_ReadWriteData_GlobalTime/E_NOT_OK, DataServices_Example_ReadWriteData_GlobalTime/DCM_E_PENDING]
        arg OpStatus: type=Dcm_OpStatusType, direction=IN
        arg Data: type=Dcm_DataElement_Example_ReadWriteData_GlobalTimeType, direction=OUT
      operation ConditionCheckRead: possible-error=[DataServices_Example_ReadWriteData_GlobalTime/E_NOT_OK, DataServices_Example_ReadWriteData_GlobalTime/DCM_E_PENDING]
        arg OpStatus: type=Dcm_OpStatusType, direction=IN
        arg ErrorCode: type=Dcm_NegativeResponseCodeType, direction=OUT
      operation WriteData: possible-error=[DataServices_Example_ReadWriteData_GlobalTime/E_NOT_OK, DataServices_Example_ReadWriteData_GlobalTime/DCM_E_PENDING]
        arg Data: type=Dcm_DataElement_Example_ReadWriteData_GlobalTimeType, direction=IN
        arg OpStatus: type=Dcm_OpStatusType, direction=IN
        arg ErrorCode: type=Dcm_NegativeResponseCodeType, direction=OUT
      error E_NOT_OK: error-code=1
      error DCM_E_PENDING: error-code=10
    DataServices_Example_ReadOnlyDID_DID_Data_GlobalTime
      operation ReadData: possible-error=[DataServices_Example_ReadOnlyDID_DID_Data_GlobalTime/E_NOT_OK, DataServices_Example_ReadOnlyDID_DID_Data_GlobalTime/DCM_E_PENDING]
        arg OpStatus: type=Dcm_OpStatusType, direction=IN
        arg Data: type=Dcm_Data6ByteType, direction=OUT
      operation ConditionCheckRead: possible-error=[DataServices_Example_ReadOnlyDID_DID_Data_GlobalTime/E_NOT_OK, DataServices_Example_ReadOnlyDID_DID_Data_GlobalTime/DCM_E_PENDING]
        arg OpStatus: type=Dcm_OpStatusType, direction=IN
        arg ErrorCode: type=Dcm_NegativeResponseCodeType, direction=OUT
      error E_NOT_OK: error-code=1
      error DCM_E_PENDING: error-code=10
package /MICROSAR/Dcm_swc/ComponentTypes
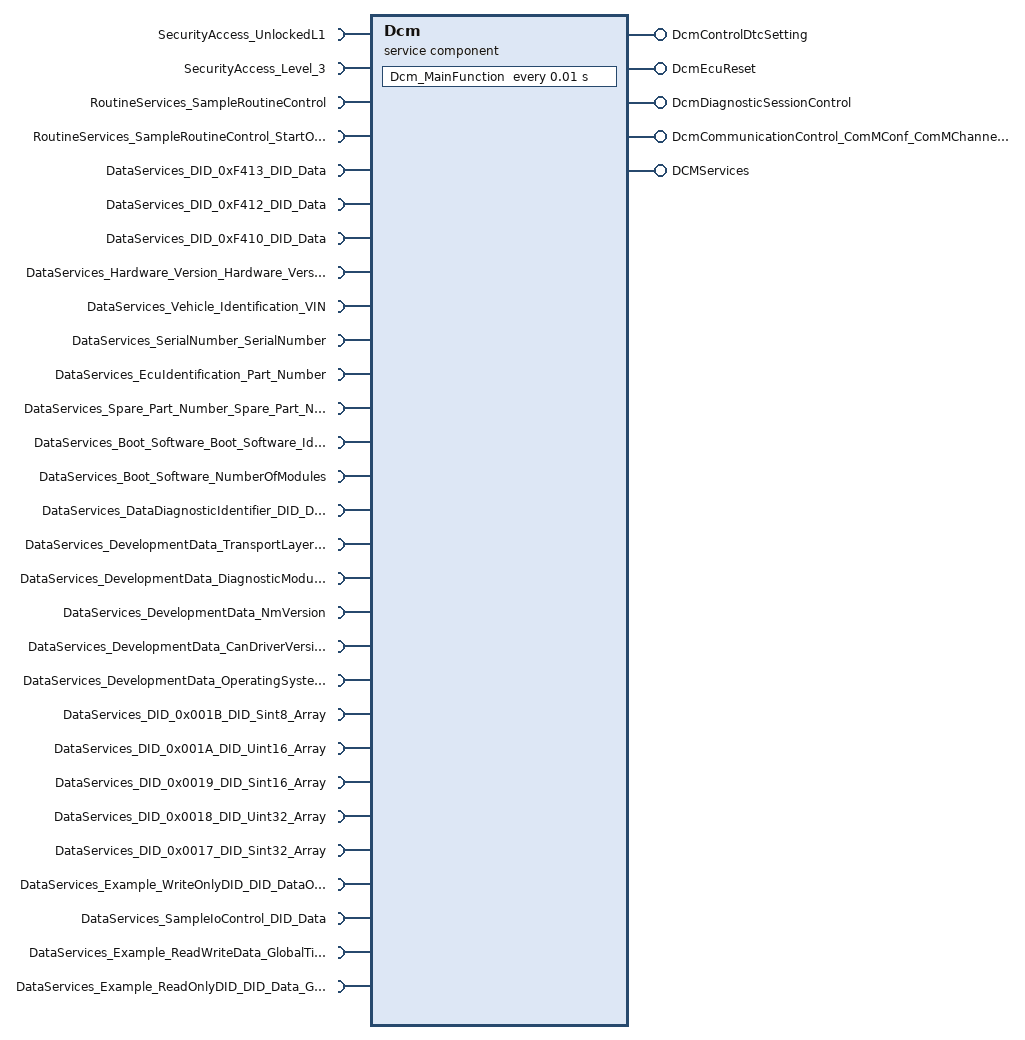
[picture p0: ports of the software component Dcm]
  service sw component type Dcm: category=SERVICE_COMPONENT
    5 x provide port:
      DcmControlDtcSetting: provided-interface=DcmControlDtcSetting
      DcmEcuReset: mode-switch-sender-com-spec{mode-group=DcmEcuReset, mode-switched-ack=timeout=0}, provided-interface=DcmEcuReset
      DcmDiagnosticSessionControl: provided-interface=DcmDiagnosticSessionControl
      DcmCommunicationControl_ComMConf_ComMChannel_CN_CAN00_a2373004: provided-interface=DcmCommunicationControl_ComMConf_ComMChannel_CN_CAN00_a2373004
      DCMServices: provided-interface=DCMServices
    29 x require port:
      SecurityAccess_UnlockedL1: required-interface=SecurityAccess_UnlockedL1
      SecurityAccess_Level_3: required-interface=SecurityAccess_Level_3
      RoutineServices_SampleRoutineControl: required-interface=RoutineServices_SampleRoutineControl
      RoutineServices_SampleRoutineControl_StartOnly: required-interface=RoutineServices_SampleRoutineControl_StartOnly
      DataServices_DID_0xF413_DID_Data: required-interface=DataServices_DID_0xF413_DID_Data
      DataServices_DID_0xF412_DID_Data: required-interface=DataServices_DID_0xF412_DID_Data
      DataServices_DID_0xF410_DID_Data: required-interface=DataServices_DID_0xF410_DID_Data
      DataServices_Hardware_Version_Hardware_Version_Number: required-interface=DataServices_Hardware_Version_Hardware_Version_Number
      DataServices_Vehicle_Identification_VIN: required-interface=DataServices_Vehicle_Identification_VIN
      DataServices_SerialNumber_SerialNumber: required-interface=DataServices_SerialNumber_SerialNumber
      DataServices_EcuIdentification_Part_Number: required-interface=DataServices_EcuIdentification_Part_Number
      DataServices_Spare_Part_Number_Spare_Part_Number: required-interface=DataServices_Spare_Part_Number_Spare_Part_Number
      DataServices_Boot_Software_Boot_Software_Identification: required-interface=DataServices_Boot_Software_Boot_Software_Identification
      DataServices_Boot_Software_NumberOfModules: required-interface=DataServices_Boot_Software_NumberOfModules
      DataServices_DataDiagnosticIdentifier_DID_DataDiagnosticIdentifier: required-interface=DataServices_DataDiagnosticIdentifier_DID_DataDiagnosticIdentifier
      DataServices_DevelopmentData_TransportLayerVersion: required-interface=DataServices_DevelopmentData_TransportLayerVersion
      DataServices_DevelopmentData_DiagnosticModuleVersion: required-interface=DataServices_DevelopmentData_DiagnosticModuleVersion
      DataServices_DevelopmentData_NmVersion: required-interface=DataServices_DevelopmentData_NmVersion
      DataServices_DevelopmentData_CanDriverVersion: required-interface=DataServices_DevelopmentData_CanDriverVersion
      DataServices_DevelopmentData_OperatingSystemVersion: required-interface=DataServices_DevelopmentData_OperatingSystemVersion
      DataServices_DID_0x001B_DID_Sint8_Array: required-interface=DataServices_DID_0x001B_DID_Sint8_Array
      DataServices_DID_0x001A_DID_Uint16_Array: required-interface=DataServices_DID_0x001A_DID_Uint16_Array
      DataServices_DID_0x0019_DID_Sint16_Array: required-interface=DataServices_DID_0x0019_DID_Sint16_Array
      DataServices_DID_0x0018_DID_Uint32_Array: required-interface=DataServices_DID_0x0018_DID_Uint32_Array
      DataServices_DID_0x0017_DID_Sint32_Array: required-interface=DataServices_DID_0x0017_DID_Sint32_Array
      DataServices_Example_WriteOnlyDID_DID_DataObject: required-interface=DataServices_Example_WriteOnlyDID_DID_DataObject
      DataServices_SampleIoControl_DID_Data: required-interface=DataServices_SampleIoControl_DID_Data
      DataServices_Example_ReadWriteData_GlobalTime: required-interface=DataServices_Example_ReadWriteData_GlobalTime
      DataServices_Example_ReadOnlyDID_DID_Data_GlobalTime: required-interface=DataServices_Example_ReadOnlyDID_DID_Data_GlobalTime
    behavior DcmInternalBehavior: data-type-mapping=DcmMappingSet, handle-termination-and-restart=NO-SUPPORT, included-data-type-set=data-type=[Dcm_ConfirmationStatusType, Dcm_OpStatusType, Dcm_NegativeResponseCodeType, Dcm_ProtocolType, Dcm_RequestKindType, Dcm_SecLevelType, Dcm_SesCtrlType, Dcm_RequestDataArrayType, Dcm_ControlDtcSettingType, Dcm_EcuResetType, Dcm_DiagnosticSessionControlType, Dcm_CommunicationModeType]
      timing event Timer_Dcm_MainFunction: start-on-event=Dcm_MainFunction, period=0.01
      6 x operation invoked event:
        OpEventGetActiveProtocol_GetActiveProtocol_DCMServices: start-on-event=GetActiveProtocol, operation=DCMServices.GetActiveProtocol
        OpEventGetSesCtrlType_GetSesCtrlType_DCMServices: start-on-event=GetSesCtrlType, operation=DCMServices.GetSesCtrlType
        OpEventResetToDefaultSession_ResetToDefaultSession_DCMServices: start-on-event=ResetToDefaultSession, operation=DCMServices.ResetToDefaultSession
        OpEventGetSecurityLevel_GetSecurityLevel_DCMServices: start-on-event=GetSecurityLevel, operation=DCMServices.GetSecurityLevel
        OpEventSetActiveDiagnostic_SetActiveDiagnostic_DCMServices: start-on-event=SetActiveDiagnostic, operation=DCMServices.SetActiveDiagnostic
        OpEventGetRequestKind_GetRequestKind_DCMServices: start-on-event=GetRequestKind, operation=DCMServices.GetRequestKind
      port-api-options:
        enable-take-address=true, indirect-api=false, port=DcmControlDtcSetting
        enable-take-address=true, indirect-api=false, port=DcmEcuReset
        enable-take-address=true, indirect-api=false, port=DcmDiagnosticSessionControl
        enable-take-address=true, indirect-api=false, port=DcmCommunicationControl_ComMConf_ComMChannel_CN_CAN00_a2373004
        enable-take-address=true, indirect-api=false, port=DCMServices
        enable-take-address=true, indirect-api=false, port=SecurityAccess_UnlockedL1
        enable-take-address=true, indirect-api=false, port=SecurityAccess_Level_3
        enable-take-address=true, indirect-api=false, port=RoutineServices_SampleRoutineControl
        enable-take-address=true, indirect-api=false, port=RoutineServices_SampleRoutineControl_StartOnly
        enable-take-address=true, indirect-api=false, port=DataServices_DID_0xF413_DID_Data
        enable-take-address=true, indirect-api=false, port=DataServices_DID_0xF412_DID_Data
        enable-take-address=true, indirect-api=false, port=DataServices_DID_0xF410_DID_Data
        enable-take-address=true, indirect-api=false, port=DataServices_Hardware_Version_Hardware_Version_Number
        enable-take-address=true, indirect-api=false, port=DataServices_Vehicle_Identification_VIN
        enable-take-address=true, indirect-api=false, port=DataServices_SerialNumber_SerialNumber
        enable-take-address=true, indirect-api=false, port=DataServices_EcuIdentification_Part_Number
        enable-take-address=true, indirect-api=false, port=DataServices_Spare_Part_Number_Spare_Part_Number
        enable-take-address=true, indirect-api=false, port=DataServices_Boot_Software_Boot_Software_Identification
        enable-take-address=true, indirect-api=false, port=DataServices_Boot_Software_NumberOfModules
        enable-take-address=true, indirect-api=false, port=DataServices_DataDiagnosticIdentifier_DID_DataDiagnosticIdentifier
        enable-take-address=true, indirect-api=false, port=DataServices_DevelopmentData_TransportLayerVersion
        enable-take-address=true, indirect-api=false, port=DataServices_DevelopmentData_DiagnosticModuleVersion
        enable-take-address=true, indirect-api=false, port=DataServices_DevelopmentData_NmVersion
        enable-take-address=true, indirect-api=false, port=DataServices_DevelopmentData_CanDriverVersion
        enable-take-address=true, indirect-api=false, port=DataServices_DevelopmentData_OperatingSystemVersion
        enable-take-address=true, indirect-api=false, port=DataServices_DID_0x001B_DID_Sint8_Array
        enable-take-address=true, indirect-api=false, port=DataServices_DID_0x001A_DID_Uint16_Array
        enable-take-address=true, indirect-api=false, port=DataServices_DID_0x0019_DID_Sint16_Array
        enable-take-address=true, indirect-api=false, port=DataServices_DID_0x0018_DID_Uint32_Array
        enable-take-address=true, indirect-api=false, port=DataServices_DID_0x0017_DID_Sint32_Array
        enable-take-address=true, indirect-api=false, port=DataServices_Example_WriteOnlyDID_DID_DataObject
        enable-take-address=true, indirect-api=false, port=DataServices_SampleIoControl_DID_Data
        enable-take-address=true, indirect-api=false, port=DataServices_Example_ReadWriteData_GlobalTime
        enable-take-address=true, indirect-api=false, port=DataServices_Example_ReadOnlyDID_DID_Data_GlobalTime
      7 x runnable:
        Dcm_MainFunction
          4 x mode switch point:
            ModeSwitchPointDcm_MainFunction_DcmControlDtcSetting_DcmControlDtcSetting: mode-group=DcmControlDtcSetting.DcmControlDtcSetting
            ModeSwitchPointDcm_MainFunction_DcmEcuReset_DcmEcuReset: mode-group=DcmEcuReset.DcmEcuReset
            ModeSwitchPointDcm_MainFunction_DcmDiagnosticSessionControl_DcmDiagnosticSessionControl: mode-group=DcmDiagnosticSessionControl.DcmDiagnosticSessionControl
            ModeSwitchPointDcm_MainFunction_DcmCommunicationControl_ComMConf_ComMChannel_CN_CAN00_a2373004_DcmCommunicationControl_52effd08: mode-group=DcmCommunicationControl_ComMConf_ComMChannel_CN_CAN00_a2373004.DcmCommunicationControl_ComMConf_ComMChannel_CN_CAN00_a2373004
          75 x sync call, all with timeout=0:
            OpServerCallDcm_MainFunction_GetSeed_SecurityAccess_UnlockedL1: operation=SecurityAccess_UnlockedL1.GetSeed
            OpServerCallDcm_MainFunction_CompareKey_SecurityAccess_UnlockedL1: operation=SecurityAccess_UnlockedL1.CompareKey
            OpServerCallDcm_MainFunction_GetSeed_SecurityAccess_Level_3: operation=SecurityAccess_Level_3.GetSeed
            OpServerCallDcm_MainFunction_CompareKey_SecurityAccess_Level_3: operation=SecurityAccess_Level_3.CompareKey
            OpServerCallDcm_MainFunction_Start_RoutineServices_SampleRoutineControl: operation=RoutineServices_SampleRoutineControl.Start
            OpServerCallDcm_MainFunction_Stop_RoutineServices_SampleRoutineControl: operation=RoutineServices_SampleRoutineControl.Stop
            OpServerCallDcm_MainFunction_RequestResults_RoutineServices_SampleRoutineControl: operation=RoutineServices_SampleRoutineControl.RequestResults
            OpServerCallDcm_MainFunction_Start_RoutineServices_SampleRoutineControl_StartOnly: operation=RoutineServices_SampleRoutineControl_StartOnly.Start
            OpServerCallDcm_MainFunction_RequestResults_RoutineServices_SampleRoutineControl_StartOnly: operation=RoutineServices_SampleRoutineControl_StartOnly.RequestResults
            OpServerCallDcm_MainFunction_ReadData_DataServices_DID_0xF413_DID_Data: operation=DataServices_DID_0xF413_DID_Data.ReadData
            OpServerCallDcm_MainFunction_ConditionCheckRead_DataServices_DID_0xF413_DID_Data: operation=DataServices_DID_0xF413_DID_Data.ConditionCheckRead
            OpServerCallDcm_MainFunction_ReadData_DataServices_DID_0xF412_DID_Data: operation=DataServices_DID_0xF412_DID_Data.ReadData
            OpServerCallDcm_MainFunction_ConditionCheckRead_DataServices_DID_0xF412_DID_Data: operation=DataServices_DID_0xF412_DID_Data.ConditionCheckRead
            OpServerCallDcm_MainFunction_ReadData_DataServices_DID_0xF410_DID_Data: operation=DataServices_DID_0xF410_DID_Data.ReadData
            OpServerCallDcm_MainFunction_ConditionCheckRead_DataServices_DID_0xF410_DID_Data: operation=DataServices_DID_0xF410_DID_Data.ConditionCheckRead
            OpServerCallDcm_MainFunction_ReadData_DataServices_Hardware_Version_Hardware_Version_Number: operation=DataServices_Hardware_Version_Hardware_Version_Number.ReadData
            OpServerCallDcm_MainFunction_ConditionCheckRead_DataServices_Hardware_Version_Hardware_Version_Number: operation=DataServices_Hardware_Version_Hardware_Version_Number.ConditionCheckRead
            OpServerCallDcm_MainFunction_WriteData_DataServices_Hardware_Version_Hardware_Version_Number: operation=DataServices_Hardware_Version_Hardware_Version_Number.WriteData
            OpServerCallDcm_MainFunction_ReadData_DataServices_Vehicle_Identification_VIN: operation=DataServices_Vehicle_Identification_VIN.ReadData
            OpServerCallDcm_MainFunction_ConditionCheckRead_DataServices_Vehicle_Identification_VIN: operation=DataServices_Vehicle_Identification_VIN.ConditionCheckRead
            OpServerCallDcm_MainFunction_WriteData_DataServices_Vehicle_Identification_VIN: operation=DataServices_Vehicle_Identification_VIN.WriteData
            OpServerCallDcm_MainFunction_ReadData_DataServices_SerialNumber_SerialNumber: operation=DataServices_SerialNumber_SerialNumber.ReadData
            OpServerCallDcm_MainFunction_ConditionCheckRead_DataServices_SerialNumber_SerialNumber: operation=DataServices_SerialNumber_SerialNumber.ConditionCheckRead
            OpServerCallDcm_MainFunction_WriteData_DataServices_SerialNumber_SerialNumber: operation=DataServices_SerialNumber_SerialNumber.WriteData
            OpServerCallDcm_MainFunction_ReadData_DataServices_EcuIdentification_Part_Number: operation=DataServices_EcuIdentification_Part_Number.ReadData
            OpServerCallDcm_MainFunction_ConditionCheckRead_DataServices_EcuIdentification_Part_Number: operation=DataServices_EcuIdentification_Part_Number.ConditionCheckRead
            OpServerCallDcm_MainFunction_WriteData_DataServices_EcuIdentification_Part_Number: operation=DataServices_EcuIdentification_Part_Number.WriteData
            OpServerCallDcm_MainFunction_ReadData_DataServices_Spare_Part_Number_Spare_Part_Number: operation=DataServices_Spare_Part_Number_Spare_Part_Number.ReadData
            OpServerCallDcm_MainFunction_ConditionCheckRead_DataServices_Spare_Part_Number_Spare_Part_Number: operation=DataServices_Spare_Part_Number_Spare_Part_Number.ConditionCheckRead
            OpServerCallDcm_MainFunction_WriteData_DataServices_Spare_Part_Number_Spare_Part_Number: operation=DataServices_Spare_Part_Number_Spare_Part_Number.WriteData
            OpServerCallDcm_MainFunction_ReadData_DataServices_Boot_Software_Boot_Software_Identification: operation=DataServices_Boot_Software_Boot_Software_Identification.ReadData
            OpServerCallDcm_MainFunction_ConditionCheckRead_DataServices_Boot_Software_Boot_Software_Identification: operation=DataServices_Boot_Software_Boot_Software_Identification.ConditionCheckRead
            OpServerCallDcm_MainFunction_WriteData_DataServices_Boot_Software_Boot_Software_Identification: operation=DataServices_Boot_Software_Boot_Software_Identification.WriteData
            OpServerCallDcm_MainFunction_ReadData_DataServices_Boot_Software_NumberOfModules: operation=DataServices_Boot_Software_NumberOfModules.ReadData
            OpServerCallDcm_MainFunction_ConditionCheckRead_DataServices_Boot_Software_NumberOfModules: operation=DataServices_Boot_Software_NumberOfModules.ConditionCheckRead
            OpServerCallDcm_MainFunction_WriteData_DataServices_Boot_Software_NumberOfModules: operation=DataServices_Boot_Software_NumberOfModules.WriteData
            OpServerCallDcm_MainFunction_ReadData_DataServices_DataDiagnosticIdentifier_DID_DataDiagnosticIdentifier: operation=DataServices_DataDiagnosticIdentifier_DID_DataDiagnosticIdentifier.ReadData
            OpServerCallDcm_MainFunction_ConditionCheckRead_DataServices_DataDiagnosticIdentifier_DID_DataDiagnosticIdentifier: operation=DataServices_DataDiagnosticIdentifier_DID_DataDiagnosticIdentifier.ConditionCheckRead
            OpServerCallDcm_MainFunction_WriteData_DataServices_DataDiagnosticIdentifier_DID_DataDiagnosticIdentifier: operation=DataServices_DataDiagnosticIdentifier_DID_DataDiagnosticIdentifier.WriteData
            OpServerCallDcm_MainFunction_ReadData_DataServices_DevelopmentData_TransportLayerVersion: operation=DataServices_DevelopmentData_TransportLayerVersion.ReadData
            OpServerCallDcm_MainFunction_ConditionCheckRead_DataServices_DevelopmentData_TransportLayerVersion: operation=DataServices_DevelopmentData_TransportLayerVersion.ConditionCheckRead
            OpServerCallDcm_MainFunction_WriteData_DataServices_DevelopmentData_TransportLayerVersion: operation=DataServices_DevelopmentData_TransportLayerVersion.WriteData
            OpServerCallDcm_MainFunction_ReadData_DataServices_DevelopmentData_DiagnosticModuleVersion: operation=DataServices_DevelopmentData_DiagnosticModuleVersion.ReadData
            OpServerCallDcm_MainFunction_ConditionCheckRead_DataServices_DevelopmentData_DiagnosticModuleVersion: operation=DataServices_DevelopmentData_DiagnosticModuleVersion.ConditionCheckRead
            OpServerCallDcm_MainFunction_WriteData_DataServices_DevelopmentData_DiagnosticModuleVersion: operation=DataServices_DevelopmentData_DiagnosticModuleVersion.WriteData
            OpServerCallDcm_MainFunction_ReadData_DataServices_DevelopmentData_NmVersion: operation=DataServices_DevelopmentData_NmVersion.ReadData
            OpServerCallDcm_MainFunction_ConditionCheckRead_DataServices_DevelopmentData_NmVersion: operation=DataServices_DevelopmentData_NmVersion.ConditionCheckRead
            OpServerCallDcm_MainFunction_WriteData_DataServices_DevelopmentData_NmVersion: operation=DataServices_DevelopmentData_NmVersion.WriteData
            OpServerCallDcm_MainFunction_ReadData_DataServices_DevelopmentData_CanDriverVersion: operation=DataServices_DevelopmentData_CanDriverVersion.ReadData
            OpServerCallDcm_MainFunction_ConditionCheckRead_DataServices_DevelopmentData_CanDriverVersion: operation=DataServices_DevelopmentData_CanDriverVersion.ConditionCheckRead
            OpServerCallDcm_MainFunction_WriteData_DataServices_DevelopmentData_CanDriverVersion: operation=DataServices_DevelopmentData_CanDriverVersion.WriteData
            OpServerCallDcm_MainFunction_ReadData_DataServices_DevelopmentData_OperatingSystemVersion: operation=DataServices_DevelopmentData_OperatingSystemVersion.ReadData
            OpServerCallDcm_MainFunction_ConditionCheckRead_DataServices_DevelopmentData_OperatingSystemVersion: operation=DataServices_DevelopmentData_OperatingSystemVersion.ConditionCheckRead
            OpServerCallDcm_MainFunction_WriteData_DataServices_DevelopmentData_OperatingSystemVersion: operation=DataServices_DevelopmentData_OperatingSystemVersion.WriteData
            OpServerCallDcm_MainFunction_WriteData_DataServices_DID_0x001B_DID_Sint8_Array: operation=DataServices_DID_0x001B_DID_Sint8_Array.WriteData
            OpServerCallDcm_MainFunction_ReadData_DataServices_DID_0x001A_DID_Uint16_Array: operation=DataServices_DID_0x001A_DID_Uint16_Array.ReadData
            OpServerCallDcm_MainFunction_ConditionCheckRead_DataServices_DID_0x001A_DID_Uint16_Array: operation=DataServices_DID_0x001A_DID_Uint16_Array.ConditionCheckRead
            OpServerCallDcm_MainFunction_WriteData_DataServices_DID_0x001A_DID_Uint16_Array: operation=DataServices_DID_0x001A_DID_Uint16_Array.WriteData
            OpServerCallDcm_MainFunction_ReadData_DataServices_DID_0x0019_DID_Sint16_Array: operation=DataServices_DID_0x0019_DID_Sint16_Array.ReadData
            OpServerCallDcm_MainFunction_ConditionCheckRead_DataServices_DID_0x0019_DID_Sint16_Array: operation=DataServices_DID_0x0019_DID_Sint16_Array.ConditionCheckRead
            OpServerCallDcm_MainFunction_ReadData_DataServices_DID_0x0018_DID_Uint32_Array: operation=DataServices_DID_0x0018_DID_Uint32_Array.ReadData
            OpServerCallDcm_MainFunction_ConditionCheckRead_DataServices_DID_0x0018_DID_Uint32_Array: operation=DataServices_DID_0x0018_DID_Uint32_Array.ConditionCheckRead
            OpServerCallDcm_MainFunction_WriteData_DataServices_DID_0x0018_DID_Uint32_Array: operation=DataServices_DID_0x0018_DID_Uint32_Array.WriteData
            OpServerCallDcm_MainFunction_WriteData_DataServices_DID_0x0017_DID_Sint32_Array: operation=DataServices_DID_0x0017_DID_Sint32_Array.WriteData
            OpServerCallDcm_MainFunction_WriteData_DataServices_Example_WriteOnlyDID_DID_DataObject: operation=DataServices_Example_WriteOnlyDID_DID_DataObject.WriteData
            OpServerCallDcm_MainFunction_ReadData_DataServices_SampleIoControl_DID_Data: operation=DataServices_SampleIoControl_DID_Data.ReadData
            OpServerCallDcm_MainFunction_ReturnControlToECU_DataServices_SampleIoControl_DID_Data: operation=DataServices_SampleIoControl_DID_Data.ReturnControlToECU
            OpServerCallDcm_MainFunction_ResetToDefault_DataServices_SampleIoControl_DID_Data: operation=DataServices_SampleIoControl_DID_Data.ResetToDefault
            OpServerCallDcm_MainFunction_FreezeCurrentState_DataServices_SampleIoControl_DID_Data: operation=DataServices_SampleIoControl_DID_Data.FreezeCurrentState
            OpServerCallDcm_MainFunction_ShortTermAdjustment_DataServices_SampleIoControl_DID_Data: operation=DataServices_SampleIoControl_DID_Data.ShortTermAdjustment
            OpServerCallDcm_MainFunction_ReadData_DataServices_Example_ReadWriteData_GlobalTime: operation=DataServices_Example_ReadWriteData_GlobalTime.ReadData
            OpServerCallDcm_MainFunction_ConditionCheckRead_DataServices_Example_ReadWriteData_GlobalTime: operation=DataServices_Example_ReadWriteData_GlobalTime.ConditionCheckRead
            OpServerCallDcm_MainFunction_WriteData_DataServices_Example_ReadWriteData_GlobalTime: operation=DataServices_Example_ReadWriteData_GlobalTime.WriteData
            OpServerCallDcm_MainFunction_ReadData_DataServices_Example_ReadOnlyDID_DID_Data_GlobalTime: operation=DataServices_Example_ReadOnlyDID_DID_Data_GlobalTime.ReadData
            OpServerCallDcm_MainFunction_ConditionCheckRead_DataServices_Example_ReadOnlyDID_DID_Data_GlobalTime: operation=DataServices_Example_ReadOnlyDID_DID_Data_GlobalTime.ConditionCheckRead
        GetActiveProtocol: can-be-invoked-concurrently=true, symbol=Dcm_GetActiveProtocol
        GetSesCtrlType: can-be-invoked-concurrently=true, symbol=Dcm_GetSesCtrlType
        ResetToDefaultSession: can-be-invoked-concurrently=true, symbol=Dcm_ResetToDefaultSession
        GetSecurityLevel: can-be-invoked-concurrently=true, symbol=Dcm_GetSecurityLevel
        SetActiveDiagnostic: can-be-invoked-concurrently=true, symbol=Dcm_SetActiveDiagnostic
        GetRequestKind: can-be-invoked-concurrently=true, symbol=Dcm_GetRequestKind
  swc implementation DcmImplementation: programming-language=C, behavior=DcmInternalBehavior
    resource consumption DcmResourceConsumption
      5 x memory section:
        Dcm_START_SEC_CODE: sw-addrmethod=CODE, symbol=CODE
        Dcm_START_SEC_CONST_UNSPECIFIED: alignment=UNSPECIFIED, sw-addrmethod=CONST, symbol=CONST_UNSPECIFIED
        Dcm_START_SEC_VAR_NOINIT_UNSPECIFIED: alignment=UNSPECIFIED, sw-addrmethod=VAR_NO_INIT, symbol=VAR_NOINIT_UNSPECIFIED
        Dcm_START_SEC_VAR_INIT_UNSPECIFIED: alignment=UNSPECIFIED, sw-addrmethod=VAR_INIT, symbol=VAR_INIT_UNSPECIFIED
        Dcm_START_SEC_VAR_ZERO_INIT_UNSPECIFIED: alignment=UNSPECIFIED, sw-addrmethod=VAR_CLEARED, symbol=VAR_ZERO_INIT_UNSPECIFIED
